# PIC32MK0512MCM100 register map
Vendor: Microchip
Registers are 32-bit, read-write, reset 0x0 unless marked. A register's access mark holds for its fields unless they carry their own. Addresses are absolute, and some are shared; only a register's first bit layout is shown; [hi:lo] are bit positions.

## I2C2
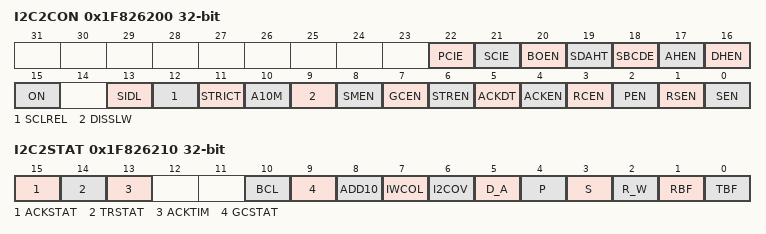
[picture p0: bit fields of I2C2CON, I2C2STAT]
0x1F826200 I2C2CON reset not defined — (power-on value ---------00000000x01000000000000)
  [22] PCIE, [21] SCIE, [20] BOEN, [19] SDAHT, [18] SBCDE, [17] AHEN, [16] DHEN, [15] ON, [13] SIDL, [12] SCLREL, [11] STRICT, [10] A10M, [9] DISSLW, [8] SMEN, [7] GCEN, [6] STREN, [5] ACKDT, [4] ACKEN, [3] RCEN, [2] PEN, [1] RSEN, [0] SEN
0x1F826210 I2C2STAT
  [15] ACKSTAT ro
  [14] TRSTAT ro
  [13] ACKTIM ro
  [10] BCL — (can only be cleared)
  [9] GCSTAT ro
  [8] ADD10 ro
  [7] IWCOL — (can only be cleared)
  [6] I2COV — (can only be cleared)
  [5] D_A ro
  [4] P — (can only be cleared)
  [3] S — (can only be cleared)
  [2] R_W ro
  [1] RBF ro
  [0] TBF ro
0x1F826220 I2C2ADD
  [9:0] I2CADD
0x1F826230 I2C2MSK
  [9:0] I2CMSK
0x1F826240 I2C2BRG
  [15:0] I2CBRG
0x1F826250 I2C2TRN wo reset 0xFF
  [7:0] I2CTRN
0x1F826260 I2C2RCV ro
  [7:0] I2CRCV

## SPI1
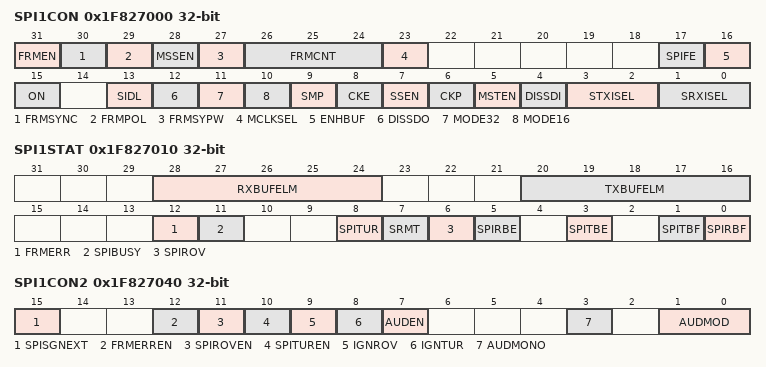
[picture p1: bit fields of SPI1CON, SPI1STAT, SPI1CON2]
0x1F827000 SPI1CON reset not defined — (power-on value 00000000x-----0000000000000x0000)
  [31] FRMEN, [30] FRMSYNC, [29] FRMPOL, [28] MSSEN, [27] FRMSYPW, [26:24] FRMCNT, [23] MCLKSEL, [17] SPIFE, [16] ENHBUF, [15] ON, [13] SIDL, [12] DISSDO, [11] MODE32, [10] MODE16, [9] SMP, [8] CKE, [7] SSEN, [6] CKP, [5] MSTEN, [4] DISSDI, [3:2] STXISEL, [1:0] SRXISEL
0x1F827010 SPI1STAT reset not defined — (power-on value ---00000---00000---x0--0000-0-00)
  [28:24] RXBUFELM ro, [20:16] TXBUFELM ro, [12] FRMERR, [11] SPIBUSY ro, [8] SPITUR ro, [7] SRMT ro, [6] SPIROV ro, [5] SPIRBE ro, [3] SPITBE ro, [1] SPITBF ro, [0] SPIRBF ro
0x1F827020 SPI1BUF reset not defined — (power-on value xxxxxxxxxxxxxxxxxxxxxxxxxxxxxxxx)
0x1F827030 SPI1BRG reset not defined — (power-on value -------------------xxxxxxxxxxxxx)
  [12:0] SPI1BRG
0x1F827040 SPI1CON2 reset not defined — (power-on value ----------------x--xxxxxx---x-xx)
  [15] SPISGNEXT, [12] FRMERREN, [11] SPIROVEN, [10] SPITUREN, [9] IGNROV, [8] IGNTUR, [7] AUDEN, [3] AUDMONO, [1:0] AUDMOD

## SPI2
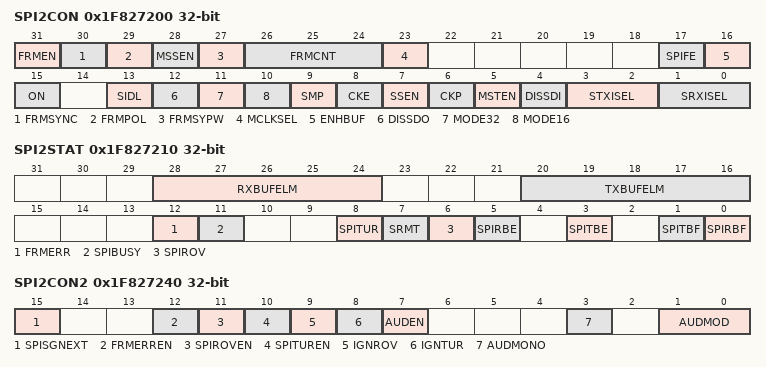
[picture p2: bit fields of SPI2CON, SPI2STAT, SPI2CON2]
0x1F827200 SPI2CON reset not defined — (power-on value 00000000x-----0000000000000x0000)
  [31] FRMEN, [30] FRMSYNC, [29] FRMPOL, [28] MSSEN, [27] FRMSYPW, [26:24] FRMCNT, [23] MCLKSEL, [17] SPIFE, [16] ENHBUF, [15] ON, [13] SIDL, [12] DISSDO, [11] MODE32, [10] MODE16, [9] SMP, [8] CKE, [7] SSEN, [6] CKP, [5] MSTEN, [4] DISSDI, [3:2] STXISEL, [1:0] SRXISEL
0x1F827210 SPI2STAT reset not defined — (power-on value ---00000---00000---x0--0000-0-00)
  [28:24] RXBUFELM ro, [20:16] TXBUFELM ro, [12] FRMERR, [11] SPIBUSY ro, [8] SPITUR ro, [7] SRMT ro, [6] SPIROV ro, [5] SPIRBE ro, [3] SPITBE ro, [1] SPITBF ro, [0] SPIRBF ro
0x1F827220 SPI2BUF reset not defined — (power-on value xxxxxxxxxxxxxxxxxxxxxxxxxxxxxxxx)
0x1F827230 SPI2BRG reset not defined — (power-on value -------------------xxxxxxxxxxxxx)
  [12:0] SPI2BRG
0x1F827240 SPI2CON2 reset not defined — (power-on value ----------------x--xxxxxx---x-xx)
  [15] SPISGNEXT, [12] FRMERREN, [11] SPIROVEN, [10] SPITUREN, [9] IGNROV, [8] IGNTUR, [7] AUDEN, [3] AUDMONO, [1:0] AUDMOD

## UART1
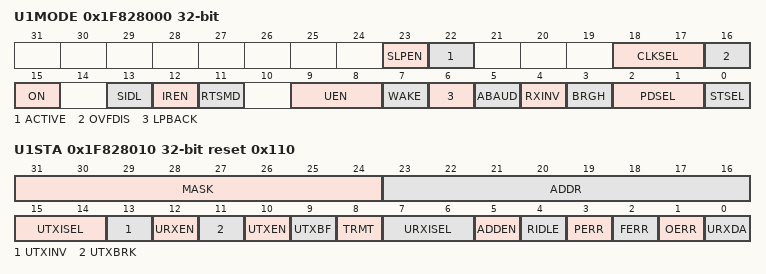
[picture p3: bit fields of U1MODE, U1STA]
0x1F828000 U1MODE
  [23] SLPEN, [22] ACTIVE, [18:17] CLKSEL, [16] OVFDIS, [15] ON, [13] SIDL, [12] IREN, [11] RTSMD, [9:8] UEN, [7] WAKE, [6] LPBACK, [5] ABAUD, [4] RXINV, [3] BRGH, [2:1] PDSEL, [0] STSEL
0x1F828010 U1STA reset 0x110
  [31:24] MASK
  [23:16] ADDR
  [15:14] UTXISEL
  [13] UTXINV
  [12] URXEN
  [11] UTXBRK
  [10] UTXEN
  [9] UTXBF ro
  [8] TRMT ro
  [7:6] URXISEL
  [5] ADDEN
  [4] RIDLE ro
  [3] PERR ro
  [2] FERR ro
  [1] OERR — (can only be cleared)
  [0] URXDA ro
0x1F828020 U1TXREG
  [8:0] U1TXREG
0x1F828030 U1RXREG ro
  [8:0] U1RXREG
0x1F828040 U1BRG
  [19:0] BRG

## UART2
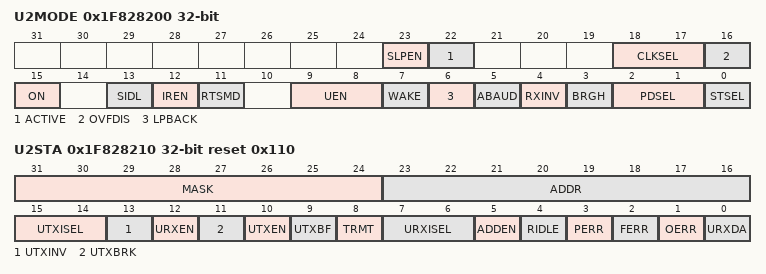
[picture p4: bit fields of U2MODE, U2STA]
0x1F828200 U2MODE
  [23] SLPEN, [22] ACTIVE, [18:17] CLKSEL, [16] OVFDIS, [15] ON, [13] SIDL, [12] IREN, [11] RTSMD, [9:8] UEN, [7] WAKE, [6] LPBACK, [5] ABAUD, [4] RXINV, [3] BRGH, [2:1] PDSEL, [0] STSEL
0x1F828210 U2STA reset 0x110
  [31:24] MASK
  [23:16] ADDR
  [15:14] UTXISEL
  [13] UTXINV
  [12] URXEN
  [11] UTXBRK
  [10] UTXEN
  [9] UTXBF ro
  [8] TRMT ro
  [7:6] URXISEL
  [5] ADDEN
  [4] RIDLE ro
  [3] PERR ro
  [2] FERR ro
  [1] OERR — (can only be cleared)
  [0] URXDA ro
0x1F828220 U2TXREG
  [8:0] U2TXREG
0x1F828230 U2RXREG ro
  [8:0] U2RXREG
0x1F828240 U2BRG
  [19:0] BRG
